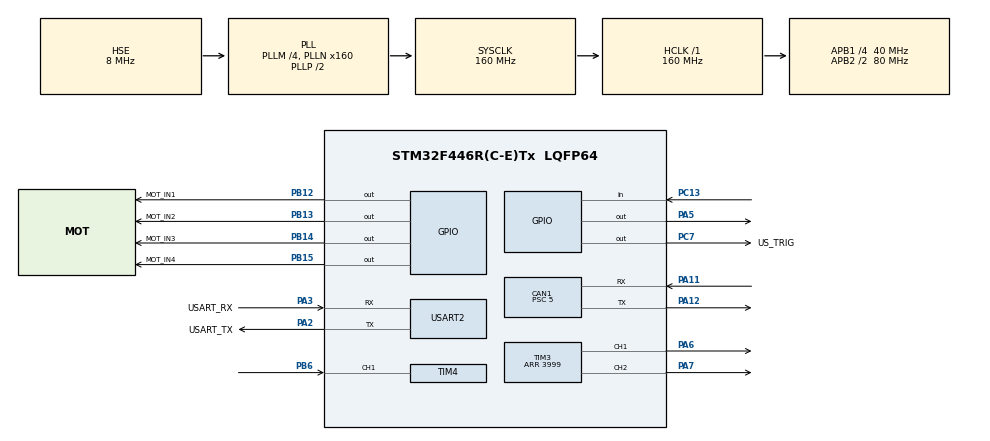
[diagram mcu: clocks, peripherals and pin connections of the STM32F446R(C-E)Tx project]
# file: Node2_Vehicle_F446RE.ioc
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CAN1.BS1=CAN_BS1_13TQ
CAN1.BS2=CAN_BS2_2TQ
CAN1.CalculateBaudRate=500000
CAN1.CalculateTimeBit=2000
CAN1.CalculateTimeQuantum=125.0
CAN1.Mode=CAN_MODE_NORMAL
CAN1.NART=ENABLE
CAN1.Prescaler=5
CAN1.SJW=CAN_SJW_2TQ
FREERTOS.Tasks01=ledTask,24,256,StartLedTask,Default,NULL,Dynamic,NULL,NULL;monitorTask,8,512,StartMonitorTask,Default,NULL,Dynamic,NULL,NULL;canRxTask,32,256,StartCanRxTask,Default,NULL,Dynamic,NULL,NULL
FREERTOS.configCHECK_FOR_STACK_OVERFLOW=2
FREERTOS.configTOTAL_HEAP_SIZE=15360
FREERTOS.configUSE_MALLOC_FAILED_HOOK=1
Mcu.Family=STM32F4
Mcu.Name=STM32F446R(C-E)Tx
Mcu.Package=LQFP64
NUCLEO-F446RE.BUTTON=1
NUCLEO-F446RE.LD1=true
NVIC.CAN1_RX0_IRQn=true\:5\:0\:false\:false\:true\:true\:true\:true\:true
NVIC.CAN1_SCE_IRQn=true\:5\:0\:false\:false\:true\:true\:true\:true\:true
NVIC.CAN1_TX_IRQn=true\:5\:0\:false\:false\:true\:true\:true\:true\:true
NVIC.EXTI15_10_IRQn=true\:5\:0\:false\:false\:true\:false\:true\:true\:true
NVIC.PriorityGroup=NVIC_PRIORITYGROUP_4
NVIC.TIM4_IRQn=true\:5\:0\:false\:false\:true\:true\:true\:true\:true
NVIC.TIM6_DAC_IRQn=true\:15\:0\:false\:false\:true\:false\:true\:true\:false
NVIC.TimeBase=TIM6_DAC_IRQn
NVIC.TimeBaseIP=TIM6
PA11.GPIO_PuPd=GPIO_PULLUP
PA11.Mode=CAN_Activate
PA11.Signal=CAN1_RX
PA12.Mode=CAN_Activate
PA12.Signal=CAN1_TX
PA13.GPIO_Label=TMS
PA13.Signal=SYS_JTMS-SWDIO
PA14.GPIO_Label=TCK
PA14.Signal=SYS_JTCK-SWCLK
PA2.GPIO_Label=USART_TX
PA2.Mode=Asynchronous
PA2.Signal=USART2_TX
PA3.GPIO_Label=USART_RX
PA3.Mode=Asynchronous
PA3.Signal=USART2_RX
PA5.Signal=GPIO_Output
PA6.Signal=S_TIM3_CH1
PA7.Signal=S_TIM3_CH2
PB12.GPIO_Label=MOT_IN1
PB12.GPIO_ModeDefaultOutputPP=GPIO_MODE_OUTPUT_PP
PB12.Signal=GPIO_Output
PB13.GPIO_Label=MOT_IN2
PB13.Signal=GPIO_Output
PB14.GPIO_Label=MOT_IN3
PB14.Signal=GPIO_Output
PB15.GPIO_Label=MOT_IN4
PB15.Signal=GPIO_Output
PB3.GPIO_Label=SWO
PB3.Signal=SYS_JTDO-SWO
PB6.Signal=S_TIM4_CH1
PC13.Signal=GPIO_Input
PC14-OSC32_IN.Signal=RCC_OSC32_IN
PC15-OSC32_OUT.Signal=RCC_OSC32_OUT
PC7.GPIO_Label=US_TRIG
PC7.Signal=GPIO_Output
PH0-OSC_IN.Mode=HSE-External-Clock-Source
PH0-OSC_IN.Signal=RCC_OSC_IN
PH1-OSC_OUT.Mode=HSE-External-Clock-Source
PH1-OSC_OUT.Signal=RCC_OSC_OUT
ProjectManager.HeapSize=0x200
ProjectManager.StackSize=0x400
ProjectManager.TargetToolchain=STM32CubeIDE
RCC.AHBFreq_Value=160000000
RCC.APB1CLKDivider=RCC_HCLK_DIV4
RCC.APB1Freq_Value=40000000
RCC.APB1TimFreq_Value=80000000
RCC.APB2CLKDivider=RCC_HCLK_DIV2
RCC.APB2Freq_Value=80000000
RCC.APB2TimFreq_Value=160000000
RCC.CortexFreq_Value=160000000
RCC.FLatency-AdvancedSettings=FLASH_LATENCY_5
RCC.HCLKFreq_Value=160000000
RCC.HSE_VALUE=8000000
RCC.HSI_VALUE=16000000
RCC.LSE_VALUE=32768
RCC.PLLM=4
RCC.PLLN=160
RCC.PLLSourceVirtual=RCC_PLLSOURCE_HSE
RCC.SYSCLKFreq_VALUE=160000000
RCC.SYSCLKSource=RCC_SYSCLKSOURCE_PLLCLK
RCC.USBFreq_Value=160000000
RCC.VCOOutputFreq_Value=320000000
SH.S_TIM3_CH1.0=TIM3_CH1,PWM Generation1 CH1
SH.S_TIM3_CH2.0=TIM3_CH2,PWM Generation2 CH2
SH.S_TIM4_CH1.0=TIM4_CH1,Input_Capture1_from_TI1
TIM3.AutoReloadPreload=TIM_AUTORELOAD_PRELOAD_ENABLE
TIM3.Channel-PWM\ Generation1\ CH1=TIM_CHANNEL_1
TIM3.Channel-PWM\ Generation2\ CH2=TIM_CHANNEL_2
TIM3.Period=3999
TIM4.Channel-Input_Capture1_from_TI1=TIM_CHANNEL_1
TIM4.Prescaler=79
USART2.VirtualMode=VM_ASYNC
VP_FREERTOS_VS_CMSIS_V2.Mode=CMSIS_V2
VP_NUCLEO-F446RE_VS_BSP_COMMON.Mode=COMMON
VP_SYS_VS_tim6.Mode=TIM6
VP_TIM3_VS_ClockSourceINT.Mode=Internal
board=NUCLEO-F446RE

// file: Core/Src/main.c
/* USER CODE BEGIN Header */
/**
  ******************************************************************************
  * @file           : main.c
  * @brief          : Main program body
  ******************************************************************************
  * @attention
  *
  * Copyright (c) 2026 STMicroelectronics.
  * All rights reserved.
  *
  * This software is licensed under terms that can be found in the LICENSE file
  * in the root directory of this software component.
  * If no LICENSE file comes with this software, it is provided AS-IS.
  *
  ******************************************************************************
  */
/* USER CODE END Header */
#include "main.h"
#include "cmsis_os.h"

/* USER CODE BEGIN Includes */
#include "m3_rtos_test.h"
#include "m3_can_test.h"
/* USER CODE END Includes */

CAN_HandleTypeDef hcan1;

TIM_HandleTypeDef htim3;
TIM_HandleTypeDef htim4;

UART_HandleTypeDef huart2;

/* Definitions for ledTask */
osThreadId_t ledTaskHandle;
const osThreadAttr_t ledTask_attributes = {
  .name = "ledTask",
  .stack_size = 256 * 4,
  .priority = (osPriority_t) osPriorityNormal,
};
/* Definitions for monitorTask */
osThreadId_t monitorTaskHandle;
const osThreadAttr_t monitorTask_attributes = {
  .name = "monitorTask",
  .stack_size = 512 * 4,
  .priority = (osPriority_t) osPriorityLow,
};
/* Definitions for canRxTask */
osThreadId_t canRxTaskHandle;
const osThreadAttr_t canRxTask_attributes = {
  .name = "canRxTask",
  .stack_size = 256 * 4,
  .priority = (osPriority_t) osPriorityAboveNormal,
};

void SystemClock_Config(void);
static void MX_GPIO_Init(void);
static void MX_TIM3_Init(void);
static void MX_USART2_UART_Init(void);
static void MX_TIM4_Init(void);
static void MX_CAN1_Init(void);
void StartLedTask(void *argument);
void StartMonitorTask(void *argument);
void StartCanRxTask(void *argument);

int main(void)
{

  /* MCU Configuration--------------------------------------------------------*/

  /* Reset of all peripherals, Initializes the Flash interface and the Systick. */
  HAL_Init();

  /* Configure the system clock */
  SystemClock_Config();

  /* Initialize all configured peripherals */
  MX_GPIO_Init();
  MX_TIM3_Init();
  MX_USART2_UART_Init();
  MX_TIM4_Init();
  MX_CAN1_Init();
  /* USER CODE BEGIN 2 */
  /* CAN starts in canRxTask after queue creation; motor PWM stays off. */
  /* USER CODE END 2 */

  /* Init scheduler */
  osKernelInitialize();

  /* USER CODE BEGIN RTOS_MUTEX */
  if (osKernelGetState() != osKernelReady) {
    M3_RtosFatal(M3_FAULT_KERNEL);
  }
  /* USER CODE END RTOS_MUTEX */

  /* USER CODE BEGIN RTOS_QUEUES */
  M3_CAN_Test_Init(&hcan1);
  /* USER CODE END RTOS_QUEUES */

  /* Create the thread(s) */
  /* creation of ledTask */
  ledTaskHandle = osThreadNew(StartLedTask, NULL, &ledTask_attributes);

  /* creation of monitorTask */
  monitorTaskHandle = osThreadNew(StartMonitorTask, NULL, &monitorTask_attributes);

  /* creation of canRxTask */
  canRxTaskHandle = osThreadNew(StartCanRxTask, NULL, &canRxTask_attributes);

  /* USER CODE BEGIN RTOS_THREADS */
  if ((ledTaskHandle == NULL) || (monitorTaskHandle == NULL) ||
      (canRxTaskHandle == NULL)) {
    M3_RtosFatal(M3_FAULT_ALLOCATION);
  }
  /* USER CODE END RTOS_THREADS */

  /* Initialize leds */
  BSP_LED_Init(LED2);

  /* Initialize USER push-button, will be used to trigger an interrupt each time it's pressed.*/
  BSP_PB_Init(BUTTON_USER, BUTTON_MODE_EXTI);

  /* Start scheduler */
  osKernelStart();

  /* We should never get here as control is now taken by the scheduler */

  /* Infinite loop */
  /* USER CODE BEGIN WHILE */
  M3_RtosFatal(M3_FAULT_KERNEL);
  while (1)
  {
    /* USER CODE END WHILE */

  }
}

void SystemClock_Config(void)
{
  RCC_OscInitTypeDef RCC_OscInitStruct = {0};
  RCC_ClkInitTypeDef RCC_ClkInitStruct = {0};

  /** Configure the main internal regulator output voltage
  */
  __HAL_RCC_PWR_CLK_ENABLE();
  __HAL_PWR_VOLTAGESCALING_CONFIG(PWR_REGULATOR_VOLTAGE_SCALE1);

  /** Initializes the RCC Oscillators according to the specified parameters
  * in the RCC_OscInitTypeDef structure.
  */
  RCC_OscInitStruct.OscillatorType = RCC_OSCILLATORTYPE_HSE;
  RCC_OscInitStruct.HSEState = RCC_HSE_BYPASS;
  RCC_OscInitStruct.PLL.PLLState = RCC_PLL_ON;
  RCC_OscInitStruct.PLL.PLLSource = RCC_PLLSOURCE_HSE;
  RCC_OscInitStruct.PLL.PLLM = 4;
  RCC_OscInitStruct.PLL.PLLN = 160;
  RCC_OscInitStruct.PLL.PLLP = RCC_PLLP_DIV2;
  RCC_OscInitStruct.PLL.PLLQ = 2;
  RCC_OscInitStruct.PLL.PLLR = 2;
  if (HAL_RCC_OscConfig(&RCC_OscInitStruct) != HAL_OK)
  {
    Error_Handler();
  }

  /** Initializes the CPU, AHB and APB buses clocks
  */
  RCC_ClkInitStruct.ClockType = RCC_CLOCKTYPE_HCLK|RCC_CLOCKTYPE_SYSCLK
                              |RCC_CLOCKTYPE_PCLK1|RCC_CLOCKTYPE_PCLK2;
  RCC_ClkInitStruct.SYSCLKSource = RCC_SYSCLKSOURCE_PLLCLK;
  RCC_ClkInitStruct.AHBCLKDivider = RCC_SYSCLK_DIV1;
  RCC_ClkInitStruct.APB1CLKDivider = RCC_HCLK_DIV4;
  RCC_ClkInitStruct.APB2CLKDivider = RCC_HCLK_DIV2;

  if (HAL_RCC_ClockConfig(&RCC_ClkInitStruct, FLASH_LATENCY_5) != HAL_OK)
  {
    Error_Handler();
  }
}

static void MX_CAN1_Init(void)
{

  hcan1.Instance = CAN1;
  hcan1.Init.Prescaler = 5;
  hcan1.Init.Mode = CAN_MODE_NORMAL;
  hcan1.Init.SyncJumpWidth = CAN_SJW_2TQ;
  hcan1.Init.TimeSeg1 = CAN_BS1_13TQ;
  hcan1.Init.TimeSeg2 = CAN_BS2_2TQ;
  hcan1.Init.TimeTriggeredMode = DISABLE;
  hcan1.Init.AutoBusOff = DISABLE;
  hcan1.Init.AutoWakeUp = DISABLE;
  hcan1.Init.AutoRetransmission = ENABLE;
  hcan1.Init.ReceiveFifoLocked = DISABLE;
  hcan1.Init.TransmitFifoPriority = DISABLE;
  if (HAL_CAN_Init(&hcan1) != HAL_OK)
  {
    Error_Handler();
  }

}

static void MX_TIM3_Init(void)
{

  TIM_ClockConfigTypeDef sClockSourceConfig = {0};
  TIM_MasterConfigTypeDef sMasterConfig = {0};
  TIM_OC_InitTypeDef sConfigOC = {0};

  htim3.Instance = TIM3;
  htim3.Init.Prescaler = 0;
  htim3.Init.CounterMode = TIM_COUNTERMODE_UP;
  htim3.Init.Period = 3999;
  htim3.Init.ClockDivision = TIM_CLOCKDIVISION_DIV1;
  htim3.Init.AutoReloadPreload = TIM_AUTORELOAD_PRELOAD_ENABLE;
  if (HAL_TIM_Base_Init(&htim3) != HAL_OK)
  {
    Error_Handler();
  }
  sClockSourceConfig.ClockSource = TIM_CLOCKSOURCE_INTERNAL;
  if (HAL_TIM_ConfigClockSource(&htim3, &sClockSourceConfig) != HAL_OK)
  {
    Error_Handler();
  }
  if (HAL_TIM_PWM_Init(&htim3) != HAL_OK)
  {
    Error_Handler();
  }
  sMasterConfig.MasterOutputTrigger = TIM_TRGO_RESET;
  sMasterConfig.MasterSlaveMode = TIM_MASTERSLAVEMODE_DISABLE;
  if (HAL_TIMEx_MasterConfigSynchronization(&htim3, &sMasterConfig) != HAL_OK)
  {
    Error_Handler();
  }
  sConfigOC.OCMode = TIM_OCMODE_PWM1;
  sConfigOC.Pulse = 0;
  sConfigOC.OCPolarity = TIM_OCPOLARITY_HIGH;
  sConfigOC.OCFastMode = TIM_OCFAST_DISABLE;
  if (HAL_TIM_PWM_ConfigChannel(&htim3, &sConfigOC, TIM_CHANNEL_1) != HAL_OK)
  {
    Error_Handler();
  }
  if (HAL_TIM_PWM_ConfigChannel(&htim3, &sConfigOC, TIM_CHANNEL_2) != HAL_OK)
  {
    Error_Handler();
  }
  HAL_TIM_MspPostInit(&htim3);

}

static void MX_TIM4_Init(void)
{

  TIM_MasterConfigTypeDef sMasterConfig = {0};
  TIM_IC_InitTypeDef sConfigIC = {0};

  htim4.Instance = TIM4;
  htim4.Init.Prescaler = 79;
  htim4.Init.CounterMode = TIM_COUNTERMODE_UP;
  htim4.Init.Period = 65535;
  htim4.Init.ClockDivision = TIM_CLOCKDIVISION_DIV1;
  htim4.Init.AutoReloadPreload = TIM_AUTORELOAD_PRELOAD_DISABLE;
  if (HAL_TIM_IC_Init(&htim4) != HAL_OK)
  {
    Error_Handler();
  }
  sMasterConfig.MasterOutputTrigger = TIM_TRGO_RESET;
  sMasterConfig.MasterSlaveMode = TIM_MASTERSLAVEMODE_DISABLE;
  if (HAL_TIMEx_MasterConfigSynchronization(&htim4, &sMasterConfig) != HAL_OK)
  {
    Error_Handler();
  }
  sConfigIC.ICPolarity = TIM_INPUTCHANNELPOLARITY_RISING;
  sConfigIC.ICSelection = TIM_ICSELECTION_DIRECTTI;
  sConfigIC.ICPrescaler = TIM_ICPSC_DIV1;
  sConfigIC.ICFilter = 0;
  if (HAL_TIM_IC_ConfigChannel(&htim4, &sConfigIC, TIM_CHANNEL_1) != HAL_OK)
  {
    Error_Handler();
  }

}

static void MX_USART2_UART_Init(void)
{

  huart2.Instance = USART2;
  huart2.Init.BaudRate = 115200;
  huart2.Init.WordLength = UART_WORDLENGTH_8B;
  huart2.Init.StopBits = UART_STOPBITS_1;
  huart2.Init.Parity = UART_PARITY_NONE;
  huart2.Init.Mode = UART_MODE_TX_RX;
  huart2.Init.HwFlowCtl = UART_HWCONTROL_NONE;
  huart2.Init.OverSampling = UART_OVERSAMPLING_16;
  if (HAL_UART_Init(&huart2) != HAL_OK)
  {
    Error_Handler();
  }

}

static void MX_GPIO_Init(void)
{
  GPIO_InitTypeDef GPIO_InitStruct = {0};

  /* GPIO Ports Clock Enable */
  __HAL_RCC_GPIOC_CLK_ENABLE();
  __HAL_RCC_GPIOH_CLK_ENABLE();
  __HAL_RCC_GPIOA_CLK_ENABLE();
  __HAL_RCC_GPIOB_CLK_ENABLE();

  /*Configure GPIO pin Output Level */
  HAL_GPIO_WritePin(GPIOB, MOT_IN1_Pin|MOT_IN2_Pin|MOT_IN3_Pin|MOT_IN4_Pin, GPIO_PIN_RESET);

  /*Configure GPIO pin Output Level */
  HAL_GPIO_WritePin(US_TRIG_GPIO_Port, US_TRIG_Pin, GPIO_PIN_RESET);

  /*Configure GPIO pins : MOT_IN1_Pin MOT_IN2_Pin MOT_IN3_Pin MOT_IN4_Pin */
  GPIO_InitStruct.Pin = MOT_IN1_Pin|MOT_IN2_Pin|MOT_IN3_Pin|MOT_IN4_Pin;
  GPIO_InitStruct.Mode = GPIO_MODE_OUTPUT_PP;
  GPIO_InitStruct.Pull = GPIO_NOPULL;
  GPIO_InitStruct.Speed = GPIO_SPEED_FREQ_LOW;
  HAL_GPIO_Init(GPIOB, &GPIO_InitStruct);

  /*Configure GPIO pin : US_TRIG_Pin */
  GPIO_InitStruct.Pin = US_TRIG_Pin;
  GPIO_InitStruct.Mode = GPIO_MODE_OUTPUT_PP;
  GPIO_InitStruct.Pull = GPIO_NOPULL;
  GPIO_InitStruct.Speed = GPIO_SPEED_FREQ_LOW;
  HAL_GPIO_Init(US_TRIG_GPIO_Port, &GPIO_InitStruct);

}

void StartLedTask(void *argument)
{
  /* USER CODE BEGIN 5 */
  M3_LedTask(argument);
  /* USER CODE END 5 */
}

void StartMonitorTask(void *argument)
{
  /* USER CODE BEGIN StartMonitorTask */
  M3_MonitorTask(argument);
  /* USER CODE END StartMonitorTask */
}

/* USER CODE BEGIN Header_StartCanRxTask */
/** @brief CAN RX queue consumer and M2-compatible echo test. */
/* USER CODE END Header_StartCanRxTask */
void StartCanRxTask(void *argument)
{
  /* USER CODE BEGIN StartCanRxTask */
  M3_CAN_Test_Task(argument);
  /* USER CODE END StartCanRxTask */
}

void HAL_TIM_PeriodElapsedCallback(TIM_HandleTypeDef *htim)
{
  if (htim->Instance == TIM6)
  {
    HAL_IncTick();
  }
}

void Error_Handler(void)
{
  /* USER CODE BEGIN Error_Handler_Debug */
  M3_RtosFatal(M3_FAULT_HAL);
  /* USER CODE END Error_Handler_Debug */
}
